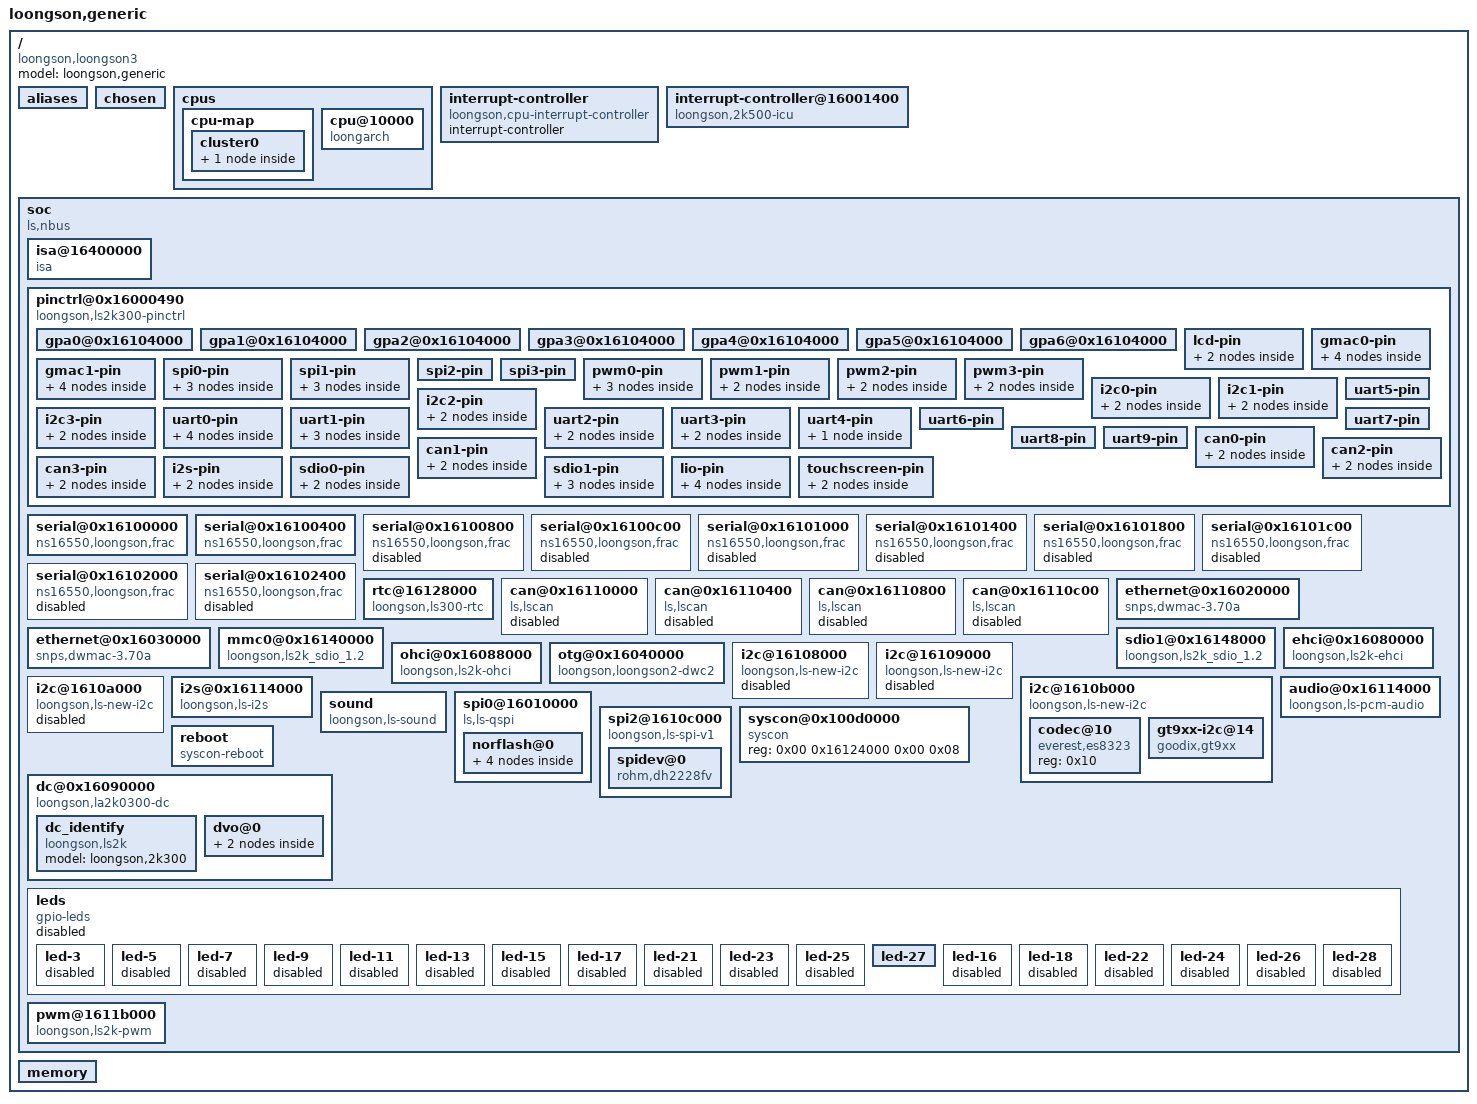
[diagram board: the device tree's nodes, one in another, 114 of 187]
/dts-v1/;

/ {
	model = "loongson,generic";
	compatible = "loongson,loongson3";
	#address-cells = <0x02>;
	#size-cells = <0x02>;

	aliases {
		ethernet0 = "/soc/ethernet@0x16020000";
		ethernet1 = "/soc/ethernet@0x16030000";
		serial0 = "/soc/serial@0x16100000";
		serial1 = "/soc/serial@0x16100400";
		serial2 = "/soc/serial@0x16100800";
		serial3 = "/soc/serial@0x16100c00";
		serial4 = "/soc/serial@0x16101000";
		serial5 = "/soc/serial@0x16101400";
		serial6 = "/soc/serial@0x16101800";
		spi0 = "/soc/spi0@16010000";
		spi2 = "/soc/spi2@1610c000";
		i2c0 = "/soc/i2c@16108000";
		i2c1 = "/soc/i2c@16109000";
		i2c2 = "/soc/i2c@1610a000";
		i2c3 = "/soc/i2c@1610b000";
	};

	chosen {
		stdout-path = "serial0:115200n8";
		bootargs = "earlycon";
	};

	cpus {
		#address-cells = <0x01>;
		#size-cells = <0x00>;

		cpu-map {

			cluster0 {

				core0 {
					cpu = <0x01>;
				};
			};
		};

		cpu@10000 {
			device_type = "cpu";
			compatible = "loongarch";
			reg = <0x00>;
			numa-node-id = <0x00>;
			phandle = <0x01>;
		};
	};

	interrupt-controller {
		compatible = "loongson,cpu-interrupt-controller";
		interrupt-controller;
		#interrupt-cells = <0x01>;
		phandle = <0x02>;
	};

	interrupt-controller@16001400 {
		compatible = "loongson,2k500-icu";
		interrupt-controller;
		#interrupt-cells = <0x01>;
		reg = <0x00 0x16001400 0x00 0x40 0x00 0x16001040 0x00 0x10>;
		interrupt-parent = <0x02>;
		interrupt-names = "cascade";
		interrupts = <0x04>;
		phandle = <0x03>;
	};

	soc {
		compatible = "ls,nbus\0simple-bus";
		#address-cells = <0x02>;
		#size-cells = <0x02>;
		ranges = <0x00 0x10000000 0x00 0x10000000 0x00 0x10000000 0x00 0x2000000 0x00 0x2000000 0x00 0x2000000 0x00 0x20000000 0x00 0x20000000 0x00 0x10000000 0x00 0x40000000 0x00 0x40000000 0x00 0x40000000 0xfe 0x00 0xfe 0x00 0x00 0x40000000>;

		isa@16400000 {
			compatible = "isa";
			#size-cells = <0x01>;
			#address-cells = <0x02>;
			ranges = <0x01 0x00 0x00 0x16400000 0x4000>;
		};

		pinctrl@0x16000490 {
			compatible = "loongson,ls2k300-pinctrl";
			reg = <0x00 0x16000490 0x00 0x10 0x00 0x16104000 0x00 0x1000>;
			loongson,regs-offset = <0x04>;
			loongson,num-chips = <0x07>;
			#address-cells = <0x02>;
			#size-cells = <0x02>;

			gpa0@0x16104000 {
				gpio-controller;
				#gpio-cells = <0x02>;
				#loongson,pinmux-cells = <0x02>;
				interrupt-controller;
				#interrupt-cells = <0x03>;
				interrupt-parent = <0x03>;
				interrupts = <0x35>;
				phandle = <0x04>;
			};

			gpa1@0x16104000 {
				gpio-controller;
				#gpio-cells = <0x02>;
				#loongson,pinmux-cells = <0x02>;
				interrupt-controller;
				#interrupt-cells = <0x03>;
				interrupt-parent = <0x03>;
				interrupts = <0x36>;
				phandle = <0x05>;
			};

			gpa2@0x16104000 {
				gpio-controller;
				#loongson,pinmux-cells = <0x02>;
				interrupt-controller;
				#interrupt-cells = <0x03>;
				interrupt-parent = <0x03>;
				interrupts = <0x37>;
				phandle = <0x06>;
			};

			gpa3@0x16104000 {
				gpio-controller;
				#gpio-cells = <0x02>;
				#loongson,pinmux-cells = <0x02>;
				interrupt-controller;
				#interrupt-cells = <0x03>;
				interrupt-parent = <0x03>;
				interrupts = <0x38>;
				phandle = <0x08>;
			};

			gpa4@0x16104000 {
				gpio-controller;
				#gpio-cells = <0x02>;
				#loongson,pinmux-cells = <0x02>;
				interrupt-controller;
				#interrupt-cells = <0x03>;
				interrupt-parent = <0x03>;
				interrupts = <0x39>;
				phandle = <0x07>;
			};

			gpa5@0x16104000 {
				gpio-controller;
				#gpio-cells = <0x02>;
				#loongson,pinmux-cells = <0x02>;
				interrupt-controller;
				#interrupt-cells = <0x03>;
				interrupt-parent = <0x03>;
				interrupts = <0x3a>;
				phandle = <0x09>;
			};

			gpa6@0x16104000 {
				gpio-controller;
				#gpio-cells = <0x02>;
				#loongson,pinmux-cells = <0x02>;
				interrupt-controller;
				#interrupt-cells = <0x03>;
				interrupt-parent = <0x03>;
				interrupts = <0x3b>;
				phandle = <0x0a>;
			};

			lcd-pin {

				lcd-pin-f0 {
					loongson,pinmux = <0x04 0x00 0x0f>;
					loongson,pinmux-funcsel = <0x03>;
					phandle = <0x24>;
				};

				lcd-pin-f1 {
					loongson,pinmux = <0x05 0x00 0x0b>;
					loongson,pinmux-funcsel = <0x03>;
					phandle = <0x25>;
				};
			};

			gmac0-pin {

				gmac0-12bit-f0 {
					loongson,pinmux = <0x05 0x0c 0x0f>;
					loongson,pinmux-funcsel = <0x03>;
					phandle = <0x11>;
				};

				gmac0-12bit-f1 {
					loongson,pinmux = <0x06 0x00 0x07>;
					loongson,pinmux-funcsel = <0x03>;
					phandle = <0x12>;
				};

				gmac0-16bit-f0 {
					loongson,pinmux = <0x06 0x08 0x09>;
					loongson,pinmux-funcsel = <0x01>;
				};

				gmac0-16bit-f1 {
					loongson,pinmux = <0x07 0x08 0x09>;
					loongson,pinmux-funcsel = <0x02>;
				};
			};

			gmac1-pin {

				gmac1-12bit-f0 {
					loongson,pinmux = <0x06 0x0c 0x0f>;
					loongson,pinmux-funcsel = <0x01>;
					phandle = <0x13>;
				};

				gmac1-12bit-f1 {
					loongson,pinmux = <0x08 0x00 0x07>;
					loongson,pinmux-funcsel = <0x01>;
					phandle = <0x14>;
				};

				gmac1-16bit-f0 {
					loongson,pinmux = <0x06 0x0a 0x0b>;
					loongson,pinmux-funcsel = <0x01>;
				};

				gmac1-16bit-f1 {
					loongson,pinmux = <0x07 0x0a 0x0b>;
					loongson,pinmux-funcsel = <0x02>;
				};
			};

			spi0-pin {

				spi0_6bit_f0 {
					loongson,pinmux = <0x08 0x08 0x0b>;
					loongson,pinmux-funcsel = <0x03>;
					phandle = <0x1f>;
				};

				spi0_6bit_f1 {
					loongson,pinmux = <0x07 0x05 0x06>;
					loongson,pinmux-funcsel = <0x01>;
					phandle = <0x20>;
				};

				spi0_7bit {
					loongson,pinmux = <0x07 0x04 0x04>;
					loongson,pinmux-funcsel = <0x01>;
				};
			};

			spi1-pin {

				spi1-4bit {
					loongson,pinmux = <0x08 0x0c 0x0f>;
					loongson,pinmux-funcsel = <0x03>;
				};

				spi1-7bit-f0 {
					loongson,pinmux = <0x07 0x0e 0x0f>;
					loongson,pinmux-funcsel = <0x02>;
				};

				spi1-7bit-f1 {
					loongson,pinmux = <0x09 0x00 0x00>;
					loongson,pinmux-funcsel = <0x02>;
				};
			};

			spi2-pin {
				loongson,pinmux = <0x07 0x00 0x03>;
				loongson,pinmux-funcsel = <0x03>;
				phandle = <0x21>;
			};

			spi3-pin {
				loongson,pinmux = <0x09 0x02 0x05>;
				loongson,pinmux-funcsel = <0x01>;
			};

			pwm0-pin {

				pwm0-mux-m0 {
					loongson,pinmux = <0x07 0x00 0x00>;
					loongson,pinmux-funcsel = <0x01>;
				};

				pwm0-mux-m1 {
					loongson,pinmux = <0x0a 0x06 0x06>;
					loongson,pinmux-funcsel = <0x02>;
				};

				pwm0-mux-m2 {
					loongson,pinmux = <0x09 0x06 0x06>;
					loongson,pinmux-funcsel = <0x02>;
					phandle = <0x27>;
				};
			};

			pwm1-pin {

				pwm1-mux-m0 {
					loongson,pinmux = <0x07 0x01 0x01>;
					loongson,pinmux-funcsel = <0x01>;
				};

				pwm1-mux-m1 {
					loongson,pinmux = <0x0a 0x07 0x07>;
					loongson,pinmux-funcsel = <0x02>;
				};
			};

			pwm2-pin {

				pwm2-mux-m0 {
					loongson,pinmux = <0x07 0x02 0x02>;
					loongson,pinmux-funcsel = <0x01>;
				};

				pwm2-mux-m1 {
					loongson,pinmux = <0x0a 0x08 0x08>;
					loongson,pinmux-funcsel = <0x02>;
				};
			};

			pwm3-pin {

				pwm3-mux-m0 {
					loongson,pinmux = <0x07 0x03 0x03>;
					loongson,pinmux-funcsel = <0x01>;
				};

				pwm3-mux-m1 {
					loongson,pinmux = <0x0a 0x09 0x09>;
					loongson,pinmux-funcsel = <0x02>;
				};
			};

			i2c0-pin {

				i2c0-mux-m0 {
					loongson,pinmux = <0x08 0x00 0x01>;
					loongson,pinmux-funcsel = <0x03>;
					phandle = <0x18>;
				};

				i2c0-mux-m1 {
					loongson,pinmux = <0x08 0x0c 0x0d>;
					loongson,pinmux-funcsel = <0x01>;
				};
			};

			i2c1-pin {

				i2c1-mux-m0 {
					loongson,pinmux = <0x08 0x02 0x03>;
					loongson,pinmux-funcsel = <0x03>;
					phandle = <0x19>;
				};

				i2c1-mux-m1 {
					loongson,pinmux = <0x08 0x0e 0x0f>;
					loongson,pinmux-funcsel = <0x01>;
				};
			};

			i2c2-pin {

				i2c2-mux-m0 {
					loongson,pinmux = <0x08 0x04 0x05>;
					loongson,pinmux-funcsel = <0x03>;
				};

				i2c2-mux-m1 {
					loongson,pinmux = <0x09 0x02 0x03>;
					loongson,pinmux-funcsel = <0x02>;
				};
			};

			i2c3-pin {

				i2c3-mux-m0 {
					loongson,pinmux = <0x08 0x06 0x07>;
					loongson,pinmux-funcsel = <0x03>;
				};

				i2c3-mux-m1 {
					loongson,pinmux = <0x09 0x04 0x05>;
					loongson,pinmux-funcsel = <0x02>;
					phandle = <0x1a>;
				};
			};

			uart0-pin {

				uart0-2bit-m0 {
					loongson,pinmux = <0x06 0x08 0x09>;
					loongson,pinmux-funcsel = <0x03>;
					phandle = <0x0b>;
				};

				uart0-2bit-m1 {
					loongson,pinmux = <0x09 0x0c 0x0d>;
					loongson,pinmux-funcsel = <0x02>;
				};

				uart0-8bit-f0 {
					loongson,pinmux = <0x08 0x0c 0x0f>;
					loongson,pinmux-funcsel = <0x02>;
				};

				uart0-8bit-f1 {
					loongson,pinmux = <0x07 0x00 0x01>;
					loongson,pinmux-funcsel = <0x02>;
				};
			};

			uart1-pin {

				uart1-2bit-m0 {
					loongson,pinmux = <0x06 0x0a 0x0b>;
					loongson,pinmux-funcsel = <0x03>;
					phandle = <0x0c>;
				};

				uart1-2bit-m1 {
					loongson,pinmux = <0x09 0x0e 0x0f>;
					loongson,pinmux-funcsel = <0x02>;
				};

				uart1-8bit {
					loongson,pinmux = <0x07 0x02 0x07>;
					loongson,pinmux-funcsel = <0x02>;
				};
			};

			uart2-pin {

				uart2-2bit-m0 {
					loongson,pinmux = <0x06 0x0c 0x0d>;
					loongson,pinmux-funcsel = <0x03>;
					phandle = <0x0d>;
				};

				uart0-2bit-m1 {
					loongson,pinmux = <0x0a 0x00 0x01>;
					loongson,pinmux-funcsel = <0x02>;
				};
			};

			uart3-pin {

				uart3-2bit-m0 {
					loongson,pinmux = <0x06 0x0e 0x0f>;
					loongson,pinmux-funcsel = <0x03>;
					phandle = <0x0e>;
				};

				uart3-2bit-m1 {
					loongson,pinmux = <0x0a 0x02 0x03>;
					loongson,pinmux-funcsel = <0x02>;
				};
			};

			uart4-pin {

				uart4-2bit {
					loongson,pinmux = <0x08 0x0e 0x0f>;
					loongson,pinmux-funcsel = <0x02>;
				};
			};

			uart5-pin {
				loongson,pinmux = <0x07 0x00 0x01>;
				loongson,pinmux-funcsel = <0x02>;
			};

			uart6-pin {
				loongson,pinmux = <0x08 0x0c 0x0d>;
				loongson,pinmux-funcsel = <0x02>;
			};

			uart7-pin {
				loongson,pinmux = <0x07 0x04 0x05>;
				loongson,pinmux-funcsel = <0x02>;
			};

			uart8-pin {
				loongson,pinmux = <0x07 0x06 0x07>;
				loongson,pinmux-funcsel = <0x02>;
			};

			uart9-pin {
				loongson,pinmux = <0x07 0x02 0x03>;
				loongson,pinmux-funcsel = <0x02>;
			};

			can0-pin {

				can0-mux-m0 {
					loongson,pinmux = <0x07 0x04 0x05>;
					loongson,pinmux-funcsel = <0x03>;
				};

				can0-mux-m1 {
					loongson,pinmux = <0x09 0x0c 0x0d>;
					loongson,pinmux-funcsel = <0x01>;
				};
			};

			can1-pin {

				can1-mux-m0 {
					loongson,pinmux = <0x07 0x06 0x07>;
					loongson,pinmux-funcsel = <0x03>;
				};

				can1-mux-m1 {
					loongson,pinmux = <0x09 0x0e 0x0f>;
					loongson,pinmux-funcsel = <0x01>;
				};
			};

			can2-pin {

				can2-mux-m0 {
					loongson,pinmux = <0x07 0x08 0x09>;
					loongson,pinmux-funcsel = <0x03>;
					phandle = <0x0f>;
				};

				can2-mux-m1 {
					loongson,pinmux = <0x0a 0x00 0x01>;
					loongson,pinmux-funcsel = <0x01>;
				};
			};

			can3-pin {

				can3-mux-m0 {
					loongson,pinmux = <0x07 0x0a 0x0b>;
					loongson,pinmux-funcsel = <0x03>;
					phandle = <0x10>;
				};

				can3-mux-m1 {
					loongson,pinmux = <0x0a 0x02 0x03>;
					loongson,pinmux-funcsel = <0x01>;
				};
			};

			i2s-pin {

				i2s-pin-f0 {
					loongson,pinmux = <0x07 0x0c 0x0f>;
					loongson,pinmux-funcsel = <0x03>;
					phandle = <0x1b>;
				};

				i2s-pin-f1 {
					loongson,pinmux = <0x09 0x00 0x00>;
					loongson,pinmux-funcsel = <0x03>;
					phandle = <0x1c>;
				};
			};

			sdio0-pin {

				sdio0-pin-f0 {
					loongson,pinmux = <0x09 0x0a 0x0f>;
					loongson,pinmux-funcsel = <0x03>;
					phandle = <0x15>;
				};

				sdio0-pin-f1 {
					loongson,pinmux = <0x0a 0x00 0x03>;
					loongson,pinmux-funcsel = <0x03>;
					phandle = <0x16>;
				};
			};

			sdio1-pin {

				sdio1-6bit {
					loongson,pinmux = <0x0a 0x04 0x09>;
					loongson,pinmux-funcsel = <0x03>;
					phandle = <0x17>;
				};

				sdio1-10bit-m0 {
					loongson,pinmux = <0x07 0x08 0x0b>;
					loongson,pinmux-funcsel = <0x01>;
				};

				sdio1-10bit-m1 {
					loongson,pinmux = <0x09 0x04 0x07>;
					loongson,pinmux-funcsel = <0x01>;
				};
			};

			lio-pin {

				lio-27bit-f0 {
					loongson,pinmux = <0x04 0x01 0x0f>;
					loongson,pinmux-funcsel = <0x02>;
				};

				lio-27bit-f1 {
					loongson,pinmux = <0x05 0x00 0x0b>;
					loongson,pinmux-funcsel = <0x02>;
				};

				lio-data-8bit {
					loongson,pinmux = <0x06 0x08 0x0f>;
					loongson,pinmux-funcsel = <0x02>;
				};

				lio-data_16bit {
					loongson,pinmux = <0x08 0x00 0x07>;
					loongson,pinmux-funcsel = <0x02>;
				};
			};

			touchscreen-pin {

				touchscreen-m0 {
					loongson,pinmux = <0x08 0x04 0x05>;
					loongson,pinmux-funcsel = <0x00>;
				};

				touchscreen-m1 {
					loongson,pinmux = <0x0a 0x07 0x08>;
					loongson,pinmux-funcsel = <0x00>;
				};
			};
		};

		serial@0x16100000 {
			#device_type = "serial";
			status = "okay";
			compatible = "ns16550,loongson,frac";
			reg = <0x00 0x16100000 0x00 0x10>;
			clock-frequency = <0x5f5e100>;
			interrupt-parent = <0x03>;
			interrupts = <0x00>;
			no-loopback-test;
			pinctrl-names = "default";
			pinctrl-0 = <0x0b>;
		};

		serial@0x16100400 {
			#device_type = "serial";
			status = "okay";
			compatible = "ns16550,loongson,frac";
			reg = <0x00 0x16100400 0x00 0x10>;
			clock-frequency = <0x5f5e100>;
			interrupt-parent = <0x03>;
			interrupts = <0x01>;
			no-loopback-test;
			pinctrl-names = "default";
			pinctrl-0 = <0x0c>;
		};

		serial@0x16100800 {
			#device_type = "serial";
			status = "disabled";
			compatible = "ns16550,loongson,frac";
			reg = <0x00 0x16100800 0x00 0x10>;
			clock-frequency = <0x5f5e100>;
			interrupt-parent = <0x03>;
			interrupts = <0x02>;
			no-loopback-test;
			pinctrl-names = "default";
			pinctrl-0 = <0x0d>;
		};

		serial@0x16100c00 {
			#device_type = "serial";
			status = "disabled";
			compatible = "ns16550,loongson,frac";
			reg = <0x00 0x16100c00 0x00 0x10>;
			clock-frequency = <0x5f5e100>;
			interrupt-parent = <0x03>;
			interrupts = <0x02>;
			no-loopback-test;
			pinctrl-names = "default";
			pinctrl-0 = <0x0e>;
		};

		serial@0x16101000 {
			#device_type = "serial";
			status = "disabled";
			compatible = "ns16550,loongson,frac";
			reg = <0x00 0x16101000 0x00 0x10>;
			clock-frequency = <0x5f5e100>;
			interrupt-parent = <0x03>;
			interrupts = <0x02>;
			no-loopback-test;
		};

		serial@0x16101400 {
			#device_type = "serial";
			status = "disabled";
			compatible = "ns16550,loongson,frac";
			reg = <0x00 0x16101400 0x00 0x10>;
			clock-frequency = <0x5f5e100>;
			interrupt-parent = <0x03>;
			interrupts = <0x02>;
			no-loopback-test;
		};

		serial@0x16101800 {
			#device_type = "serial";
			status = "disabled";
			compatible = "ns16550,loongson,frac";
			reg = <0x00 0x16101800 0x00 0x10>;
			clock-frequency = <0x5f5e100>;
			interrupt-parent = <0x03>;
			interrupts = <0x03>;
			no-loopback-test;
		};

		serial@0x16101c00 {
			#device_type = "serial";
			status = "disabled";
			compatible = "ns16550,loongson,frac";
			reg = <0x00 0x16101c00 0x00 0x10>;
			clock-frequency = <0x5f5e100>;
			interrupt-parent = <0x03>;
			interrupts = <0x03>;
			no-loopback-test;
		};

		serial@0x16102000 {
			#device_type = "serial";
			status = "disabled";
			compatible = "ns16550,loongson,frac";
			reg = <0x00 0x16102000 0x00 0x10>;
			clock-frequency = <0x5f5e100>;
			interrupt-parent = <0x03>;
			interrupts = <0x03>;
			no-loopback-test;
		};

		serial@0x16102400 {
			#device_type = "serial";
			status = "disabled";
			compatible = "ns16550,loongson,frac";
			reg = <0x00 0x16102400 0x00 0x10>;
			clock-frequency = <0x5f5e100>;
			interrupt-parent = <0x03>;
			interrupts = <0x03>;
			no-loopback-test;
		};

		rtc@16128000 {
			compatible = "loongson,ls300-rtc";
			reg = <0x00 0x16128000 0x00 0x100>;
			interrupt-parent = <0x03>;
			interrupts = <0x28>;
			status = "okay";
		};

		can@0x16110000 {
			compatible = "ls,lscan";
			status = "disabled";
			reg = <0x00 0x16110000 0x00 0x400>;
			ls,clock-frequency = <0x5f5e100>;
			#interrupt-cells = <0x02>;
			interrupt-parent = <0x03>;
			interrupts = <0x08>;
		};

		can@0x16110400 {
			compatible = "ls,lscan";
			status = "disabled";
			reg = <0x00 0x16110400 0x00 0x400>;
			ls,clock-frequency = <0x5f5e100>;
			#interrupt-cells = <0x02>;
			interrupt-parent = <0x03>;
			interrupts = <0x09>;
		};

		can@0x16110800 {
			compatible = "ls,lscan";
			status = "disabled";
			reg = <0x00 0x16110800 0x00 0x400>;
			ls,clock-frequency = <0x5f5e100>;
			#interrupt-cells = <0x02>;
			interrupt-parent = <0x03>;
			interrupts = <0x0a>;
			pinctrl-names = "default";
			pinctrl-0 = <0x0f>;
		};

		can@0x16110c00 {
			compatible = "ls,lscan";
			status = "disabled";
			reg = <0x00 0x16110c00 0x00 0x400>;
			ls,clock-frequency = <0x5f5e100>;
			#interrupt-cells = <0x02>;
			interrupt-parent = <0x03>;
			interrupts = <0x0b>;
			pinctrl-names = "default";
			pinctrl-0 = <0x10>;
		};

		ethernet@0x16020000 {
			status = "okay";
			compatible = "snps,dwmac-3.70a";
			reg = <0x00 0x16020000 0x00 0x10000>;
			interrupt-parent = <0x03>;
			interrupts = <0x31>;
			interrupt-names = "macirq";
			mac-address = [64 48 48 48 48 60];
			phy-mode = "rgmii";
			bus_id = <0x00>;
			phy_addr = <0xffffffff>;
			dma-mask = <0xffffffff 0xffffffff>;
			pinctrl-names = "default";
			pinctrl-0 = <0x11 0x12>;
		};

		ethernet@0x16030000 {
			status = "okay";
			compatible = "snps,dwmac-3.70a";
			reg = <0x00 0x16030000 0x00 0x10000>;
			interrupt-parent = <0x03>;
			interrupts = <0x32>;
			interrupt-names = "macirq";
			mac-address = [64 48 48 48 48 61];
			phy-mode = "rgmii";
			bus_id = <0x01>;
			phy_addr = <0xffffffff>;
			dma-mask = <0xffffffff 0xffffffff>;
			pinctrl-names = "default";
			pinctrl-0 = <0x13 0x14>;
		};

		mmc0@0x16140000 {
			status = "okay";
			#address-cells = <0x02>;
			compatible = "loongson,ls2k_sdio_1.2";
			reg = <0x00 0x16140000 0x00 0x1000>;
			interrupt-parent = <0x03>;
			interrupts = <0x1f>;
			interrupt-names = "ls2k_mci_irq";
			dma-mask = <0xffffffff 0xffffffff>;
			clock-frequency = <0x00 0x5f5e100>;
			bus-width = <0x08>;
			mmc-hs200-1_8v;
			no-sd;
			no-sdio;
			non-removable;
			pinctrl-names = "default";
			pinctrl-0 = <0x15 0x16>;
		};

		sdio1@0x16148000 {
			status = "okay";
			#address-cells = <0x02>;
			compatible = "loongson,ls2k_sdio_1.2";
			reg = <0x00 0x16148000 0x00 0x1000>;
			interrupt-parent = <0x03>;
			interrupts = <0x20>;
			interrupt-names = "ls2k_mci_irq";
			clock-frequency = <0x00 0x5f5e100>;
			dma-mask = <0xffffffff 0xffffffff>;
			bus-width = <0x04>;
			cap-sd-highspeed;
			no-mmc;
			pinctrl-names = "default";
			pinctrl-0 = <0x17>;
		};

		ehci@0x16080000 {
			status = "okay";
			compatible = "loongson,ls2k-ehci\0generic-ehci";
			reg = <0x00 0x16080000 0x00 0x8000>;
			interrupt-parent = <0x03>;
			interrupts = <0x2e>;
			dma-mask = <0xffffffff 0xffffffff>;
		};

		ohci@0x16088000 {
			status = "okay";
			compatible = "loongson,ls2k-ohci\0generic-ohci";
			reg = <0x00 0x16088000 0x00 0x8000>;
			interrupt-parent = <0x03>;
			interrupts = <0x2f>;
			dma-mask = <0x00 0xffffffff>;
		};

		otg@0x16040000 {
			status = "okay";
			compatible = "loongson,loongson2-dwc2\0loongson,ls2k-otg";
			reg = <0x00 0x16040000 0x00 0x40000>;
			interrupt-parent = <0x03>;
			interrupts = <0x30>;
			dma-mask = <0x00 0xffffffff>;
		};

		i2c@16108000 {
			status = "disabled";
			compatible = "loongson,ls-new-i2c";
			reg = <0x00 0x16108000 0x00 0x400>;
			interrupt-parent = <0x03>;
			interrupts = <0x04>;
			#address-cells = <0x01>;
			#size-cells = <0x00>;
			clock-frequency = <0x186a0>;
			pinctrl-names = "default";
			pinctrl-0 = <0x18>;
		};

		i2c@16109000 {
			status = "disabled";
			compatible = "loongson,ls-new-i2c";
			reg = <0x00 0x16109000 0x00 0x400>;
			interrupt-parent = <0x03>;
			interrupts = <0x04>;
			#address-cells = <0x01>;
			#size-cells = <0x00>;
			clock-frequency = <0x61a80>;
			pinctrl-names = "default";
			pinctrl-0 = <0x19>;
		};

		i2c@1610a000 {
			status = "disabled";
			compatible = "loongson,ls-new-i2c";
			reg = <0x00 0x1610a000 0x00 0x400>;
			interrupt-parent = <0x03>;
			interrupts = <0x05>;
			#address-cells = <0x01>;
			#size-cells = <0x00>;
		};

		i2c@1610b000 {
			status = "okay";
			compatible = "loongson,ls-new-i2c";
			reg = <0x00 0x1610b000 0x00 0x400>;
			interrupt-parent = <0x03>;
			interrupts = <0x05>;
			#address-cells = <0x01>;
			#size-cells = <0x00>;
			clock-frequency = <0x186a0>;
			pinctrl-names = "default";
			pinctrl-0 = <0x1a>;

			codec@10 {
				compatible = "everest,es8323";
				reg = <0x10>;
			};

			gt9xx-i2c@14 {
				status = "okay";
				compatible = "goodix,gt9xx";
				reg = <0x14>;
				reset-gpios = <0x09 0x08 0x00>;
				irq-gpios = <0x09 0x09 0x00>;
				irq-flags = <0x02>;
				goodix,type-a-report = <0x00>;
				goodix,driver-send-cfg = <0x00>;
				goodix,create-wr-node = <0x01>;
				goodix,wakeup-with-reset = <0x00>;
				goodix,resume-in-workqueue = <0x00>;
				goodix,int-sync = <0x01>;
				goodix,swap-x2y = <0x00>;
				goodix,esd-protect = <0x00>;
				goodix,auto-update = <0x01>;
				goodix,auto-update-cfg = <0x00>;
				goodix,power-off-sleep = <0x00>;
				goodix.pen-suppress-finger = <0x00>;
				goodix,cfg-group0 = [53 d0 02 00 05 05 f5 d5 21 48 2d 0f 5a 41 0e 05 00 00 32 32 20 00 05 14 14 1a 14 8b 2b 00];
			};
		};

		i2s@0x16114000 {
			status = "okay";
			compatible = "loongson,ls-i2s";
			reg = <0x00 0x16114000 0x00 0x10>;
			clock-frequency = <0x5f5e100>;
			pinctrl-names = "default";
			pinctrl-0 = <0x1b 0x1c>;
			phandle = <0x1d>;
		};

		audio@0x16114000 {
			compatible = "loongson,ls-pcm-audio";
			reg = <0x00 0x16114000 0x00 0x10>;
			interrupt-parent = <0x03>;
			interrupts = <0x18 0x17>;
			interrupt-names = "i2s_irq0\0i2s_irq1";
			dma-base = <0x00 0x1612c000>;
			play-chan = <0x01>;
			record-chan = <0x00>;
			dma-names = "i2s_play\0i2s_record";
			dma-mask = <0xffffffff 0xffffffff>;
			phandle = <0x1e>;
		};

		sound {
			compatible = "loongson,ls-sound";
			loongson,i2s-controller = <0x1d>;
			loongson,audio-codec = <0x1e>;
			codec-names = "ES8323 PAIF RX\0Playback\0ES8323 HiFi\0ES8323.3-0010\0ES8323 PAIF TX\0Capture\0ES8323 HiFi\0ES8323.3-0010";
		};

		spi0@16010000 {
			status = "okay";
			compatible = "ls,ls-qspi";
			reg = <0x00 0x16010000 0x00 0x10>;
			reg-names = "qspi";
			#address-cells = <0x01>;
			#size-cells = <0x00>;
			pinctrl-names = "default";
			pinctrl-0 = <0x1f 0x20>;

			norflash@0 {
				reg = <0x00>;
				spi-rx-bus-width = <0x04>;
				spi-max-frequency = <0x17d7840>;
				#address-cells = <0x01>;
				#size-cells = <0x01>;

				partitions {
					compatible = "fixed-partitions";
					#address-cells = <0x01>;
					#size-cells = <0x01>;

					boot@0 {
						label = "boot";
						reg = <0x00 0x100000>;
					};

					kernel@100000 {
						label = "kernel";
						reg = <0x100000 0x600000>;
					};

					rootfs@700000 {
						label = "rootfs";
						reg = <0x700000 0x1000000>;
					};
				};
			};
		};

		spi2@1610c000 {
			compatible = "loongson,ls-spi-v1";
			status = "okay";
			#address-cells = <0x01>;
			#size-cells = <0x00>;
			reg = <0x00 0x1610c000 0x00 0x1000>;
			spi-max-frequency = <0x2faf080>;
			interrupt-parent = <0x03>;
			interrupts = <0x06>;
			num-cs = <0x01>;
			ls,bus_num = <0x01>;
			pinctrl-names = "default";
			pinctrl-0 = <0x21>;

			spidev@0 {
				compatible = "rohm,dh2228fv";
				spi-max-frequency = <0x2faf080>;
				reg = <0x00>;
			};
		};

		syscon@0x100d0000 {
			compatible = "syscon";
			reg = <0x00 0x16124000 0x00 0x08>;
			phandle = <0x22>;
		};

		reboot {
			compatible = "syscon-reboot";
			regmap = <0x22>;
			offset = <0x00>;
			mask = <0x01>;
		};

		dc@0x16090000 {
			status = "okay";
			compatible = "loongson,la2k0300-dc";
			reg = <0x00 0x16090000 0x00 0x10000>;
			interrupt-parent = <0x03>;
			interrupts = <0x33>;
			dma-mask = <0x00 0xffffffff>;
			output-ports = <0x23>;
			#address-cells = <0x01>;
			#size-cells = <0x00>;
			pinctrl-names = "default";
			pinctrl-0 = <0x24 0x25>;

			dc_identify {
				model = "loongson,2k300";
				compatible = "loongson,ls2k";
			};

			dvo@0 {
				reg = <0x00>;
				connector = "dpi-connector";
				status = "ok";
				phandle = <0x23>;

				display-timings {
					native-mode = <0x26>;

					display-timing@0 {
						clock-frequency = <0x30d4000>;
						hactive = <0x400>;
						hfront-porch = <0xa0>;
						hsync-len = <0x04>;
						hback-porch = <0x9c>;
						vactive = <0x258>;
						vfront-porch = <0x0b>;
						vsync-len = <0x01>;
						vback-porch = <0x17>;
						vsync-active = <0x00>;
						hsync-active = <0x00>;
						phandle = <0x26>;
					};
				};
			};
		};

		leds {
			status = "disabled";
			compatible = "gpio-leds";

			led-3 {
				status = "disabled";
				label = "led3";
				gpios = <0x07 0x09 0x00>;
				default-state = "off";
			};

			led-5 {
				status = "disabled";
				label = "led5";
				gpios = <0x07 0x08 0x00>;
				default-state = "off";
			};

			led-7 {
				status = "disabled";
				label = "led7";
				gpios = <0x07 0x0b 0x00>;
				default-state = "off";
			};

			led-9 {
				status = "disabled";
				label = "led9";
				gpios = <0x07 0x0a 0x00>;
				default-state = "off";
			};

			led-11 {
				status = "disabled";
				label = "led11";
				gpios = <0x08 0x02 0x00>;
				default-state = "off";
			};

			led-13 {
				status = "disabled";
				label = "led13";
				gpios = <0x08 0x03 0x00>;
				default-state = "off";
			};

			led-15 {
				status = "disabled";
				label = "led15";
				gpios = <0x09 0x05 0x00>;
				default-state = "off";
			};

			led-17 {
				status = "disabled";
				label = "led17";
				gpios = <0x09 0x04 0x00>;
				default-state = "off";
			};

			led-21 {
				status = "disabled";
				label = "led21";
				gpios = <0x07 0x00 0x00>;
				default-state = "off";
			};

			led-23 {
				status = "disabled";
				label = "led23";
				gpios = <0x07 0x03 0x00>;
				default-state = "off";
			};

			led-25 {
				status = "disabled";
				label = "led25";
				gpios = <0x07 0x01 0x00>;
				default-state = "off";
			};

			led-27 {
				status = "okay";
				label = "led27";
				gpios = <0x07 0x02 0x00>;
				default-state = "off";
			};

			led-16 {
				status = "disabled";
				label = "led16";
				gpios = <0x08 0x00 0x00>;
				default-state = "off";
			};

			led-18 {
				status = "disabled";
				label = "led18";
				gpios = <0x08 0x01 0x00>;
				default-state = "off";
			};

			led-22 {
				status = "disabled";
				label = "led22";
				gpios = <0x08 0x0c 0x00>;
				default-state = "off";
			};

			led-24 {
				status = "disabled";
				label = "led24";
				gpios = <0x08 0x0f 0x00>;
				default-state = "off";
			};

			led-26 {
				status = "disabled";
				label = "led26";
				gpios = <0x08 0x0d 0x00>;
				default-state = "off";
			};

			led-28 {
				status = "disabled";
				label = "led28";
				gpios = <0x08 0x0e 0x00>;
				default-state = "off";
			};
		};

		pwm@1611b000 {
			compatible = "loongson,ls2k-pwm";
			reg = <0x00 0x1611b000 0x00 0x10>;
			clock-frequency = <0x5f5e100>;
			interrupt-parent = <0x03>;
			interrupts = <0x10 0x04>;
			#pwm-cells = <0x02>;
			status = "okay";
			pinctrl-names = "default";
			pinctrl-0 = <0x27>;
		};
	};

	memory {
		device_type = "memory";
		reg = <0x00 0x200000 0x00 0xee00000 0x00 0x90000000 0x00 0x30000000>;
	};
};
